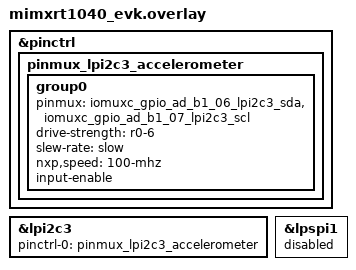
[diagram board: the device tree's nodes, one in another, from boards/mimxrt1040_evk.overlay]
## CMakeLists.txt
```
# SPDX-License-Identifier: Apache-2.0

cmake_minimum_required(VERSION 3.20.0)
#set(CMAKE_FIND_DEBUG_MODE 1)
find_package(Zephyr REQUIRED HINTS $ENV{ZEPHYR_BASE})
project(fxls8974)

FILE(GLOB app_sources src/*.c)
target_sources(app PRIVATE ${app_sources})
#add_library(set-app-flags INTERFACE)
#target_compile_options(set-app-flags INTERFACE -O0)
#target_link_libraries(app PRIVATE set-app-flags)
```

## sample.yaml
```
common:
  harness: sensor
  tags: sensors
  depends_on:
    - i2c
    - gpio
sample:
  name: FXOS8974 Accelerometer
tests:
 sample.sensor.fxls8974.accel:
    platform_allow:
      - mimxrt685_evk/mimxrt685s/cm33
      - mimxrt595_evk/mimxrt595s/cm33
```

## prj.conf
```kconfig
CONFIG_STDOUT_CONSOLE=y
CONFIG_LOG=y
CONFIG_I2C=y
CONFIG_SENSOR=y
CONFIG_SENSOR_LOG_LEVEL_DBG=y
CONFIG_FXLS8974_TRIGGER_OWN_THREAD=y
CONFIG_FXLS8974_MOTION=y
CONFIG_CBPRINTF_FP_SUPPORT=y
CONFIG_DEBUG=y
```

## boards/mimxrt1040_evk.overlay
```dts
/*
 * Copyright (c) 2024 NXP
 *
 * SPDX-License-Identifier: Apache-2.0
 */

&pinctrl {
	pinmux_lpi2c3_accelerometer: pinmux_lpi2c3_accelerometer {
		group0{
			pinmux = <&iomuxc_gpio_ad_b1_06_lpi2c3_sda>,
				<&iomuxc_gpio_ad_b1_07_lpi2c3_scl>;
			drive-strength = "r0-6";
			slew-rate = "slow";
			nxp,speed = "100-mhz";
			input-enable;
		};
	};
};

&lpi2c3 {
	pinctrl-0 = <&pinmux_lpi2c3_accelerometer>;
	status = "okay";
};

&lpspi1{
	status = "disabled";
};
```

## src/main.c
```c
/*
 * Copyright (c) 2016 Freescale Semiconductor, Inc.
 * Copyright (c) 2018 Phytec Messtechnik GmbH
 *
 * SPDX-License-Identifier: Apache-2.0
 */

#include <zephyr/kernel.h>
#include <zephyr/drivers/sensor.h>
#include <stdio.h>

K_SEM_DEFINE(sem, 0, 1);	/* starts off "not available" */

#if !defined(CONFIG_FXLS8974_TRIGGER_NONE)
static void trigger_handler(const struct device *dev,
			    const struct sensor_trigger *trigger)
{
	ARG_UNUSED(trigger);

	/* Always fetch the sample to clear the data ready interrupt in the
	 * sensor.
	 */
	if (sensor_sample_fetch(dev)) {
		printf("sensor_sample_fetch failed\n");
		return;
	}

	k_sem_give(&sem);
}
#endif /* !CONFIG_FXLS8974_TRIGGER_NONE */

int main(void)
{
	struct sensor_value accel[3];
	const struct device *const dev = DEVICE_DT_GET_ONE(nxp_fxls8974);

	if (!device_is_ready(dev)) {
		printf("Device %s is not ready\n", dev->name);
		return 0;
	}

	struct sensor_value attr = {
		.val1 = 6,
		.val2 = 250000,
	};

	if (sensor_attr_set(dev, SENSOR_CHAN_ALL,
			    SENSOR_ATTR_SAMPLING_FREQUENCY, &attr)) {
		printk("Could not set sampling frequency\n");
		return 0;
	}

#ifdef CONFIG_FXLS8974_MOTION
	attr.val1 = 10;
	attr.val2 = 600000;
	if (sensor_attr_set(dev, SENSOR_CHAN_ALL,
			    SENSOR_ATTR_SLOPE_TH, &attr)) {
		printk("Could not set slope threshold\n");
		return 0;
	}
#endif

#if !defined(CONFIG_FXLS8974_TRIGGER_NONE)
	struct sensor_trigger trig = {
#ifdef CONFIG_FXLS8974_MOTION
		.type = SENSOR_TRIG_DELTA,
#else
		.type = SENSOR_TRIG_DATA_READY,
#endif
		.chan = SENSOR_CHAN_ACCEL_XYZ,
	};

	if (sensor_trigger_set(dev, &trig, trigger_handler)) {
		printf("Could not set trigger\n");
		return 0;
	}
#endif /* !CONFIG_FXLS8974_TRIGGER_NONE */

	while (1) {
#ifdef CONFIG_FXLS8974_TRIGGER_NONE
		//k_sleep(K_MSEC(160));
		k_sleep(K_MSEC(5000));
		sensor_sample_fetch(dev);
#else
		k_sem_take(&sem, K_FOREVER);
#endif
		sensor_channel_get(dev, SENSOR_CHAN_ACCEL_XYZ, accel);
		/* Print accel x,y,z data */
		printf("AX=%10.6f AY=%10.6f AZ=%10.6f ",
		       sensor_value_to_double(&accel[0]),
		       sensor_value_to_double(&accel[1]),
		       sensor_value_to_double(&accel[2]));
		printf("\n");
	}
}
```
